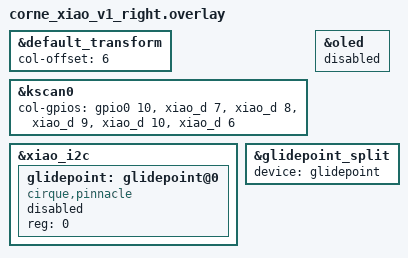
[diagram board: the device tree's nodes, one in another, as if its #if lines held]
#include "corne_xiao_v1.dtsi"
#include "corne_xiao_v1_trackpad.dtsi"

&default_transform {
    col-offset = <6>;
};

&kscan0 {
    col-gpios
        = <&gpio0 10 GPIO_ACTIVE_HIGH>
        , <&xiao_d 7 GPIO_ACTIVE_HIGH>
        , <&xiao_d 8 GPIO_ACTIVE_HIGH>
        , <&xiao_d 9 GPIO_ACTIVE_HIGH>
        , <&xiao_d 10 GPIO_ACTIVE_HIGH>
        , <&xiao_d 6 GPIO_ACTIVE_HIGH>
        ;
};

#if defined(CONFIG_CORNE_XIAO_RIGHT_TRACKPAD)
// Trackpad replaces the OLED on the right half (both use the xiao_i2c bus).
&oled {
    status = "disabled";
};

&xiao_i2c {
    glidepoint: glidepoint@0 {
        compatible = "cirque,pinnacle";
        reg = <0>;
        status = "disabled";
        // NOTE: enable ("okay") + set correct cirque properties when the
        // trackpad is installed. See the cirque-pinnacle module docs for the
        // available sensitivity/sleep/glidepoint properties.
    };
};

&glidepoint_split {
    device = <&glidepoint>;
};
#endif
